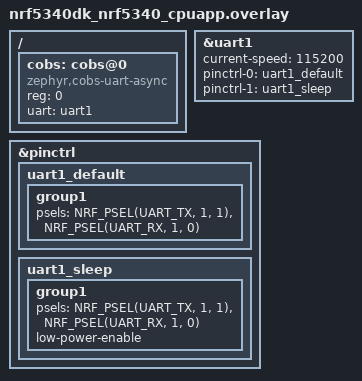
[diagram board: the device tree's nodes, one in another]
/*
 * Copyright (c) 2024 Nordic Semiconductor ASA
 *
 * SPDX-License-Identifier: Apache-2.0
 */

/ {
	#size-cells = <0>;

	cobs: cobs@0 {
		compatible = "zephyr,cobs-uart-async";
		reg = <0>;
		uart = <&uart1>;
		status = "okay";
	};
};

/* Configure UART1 for SLIP interface */
&uart1 {
	status = "okay";
	current-speed = <115200>;
	pinctrl-0 = <&uart1_default>;
	pinctrl-1 = <&uart1_sleep>;
	pinctrl-names = "default", "sleep";
};

&pinctrl {
	uart1_default: uart1_default {
		group1 {
			psels = <NRF_PSEL(UART_TX, 1, 1)>,
				<NRF_PSEL(UART_RX, 1, 0)>;
		};
	};

	uart1_sleep: uart1_sleep {
		group1 {
			psels = <NRF_PSEL(UART_TX, 1, 1)>,
				<NRF_PSEL(UART_RX, 1, 0)>;
			low-power-enable;
		};
	};
};

